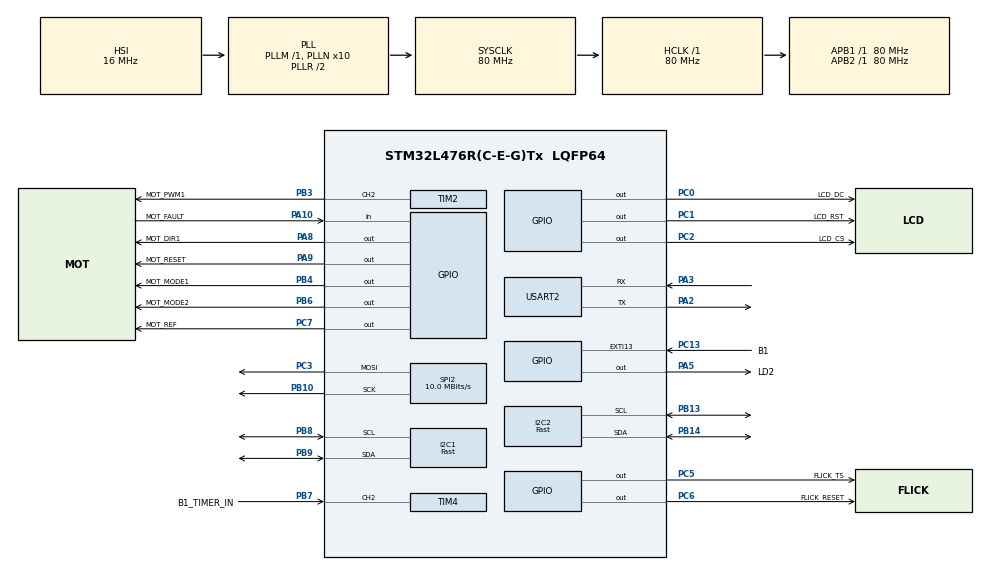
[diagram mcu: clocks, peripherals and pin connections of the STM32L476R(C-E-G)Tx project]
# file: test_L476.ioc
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I2C1.I2C_Speed_Mode=I2C_Fast
I2C1.OwnAddress=0x42
I2C1.Timing=0x00702991
I2C2.I2C_Speed_Mode=I2C_Fast
I2C2.Timing=0x00702991
Mcu.Family=STM32L4
Mcu.Name=STM32L476R(C-E-G)Tx
Mcu.Package=LQFP64
NVIC.PriorityGroup=NVIC_PRIORITYGROUP_4
NVIC.TIM2_IRQn=true\:0\:0\:false\:false\:true\:true\:true
PA10.GPIO_Label=MOT_FAULT
PA10.GPIO_Mode=GPIO_MODE_INPUT
PA10.GPIO_PuPd=GPIO_NOPULL
PA10.Signal=GPIO_Input
PA13\ (JTMS-SWDIO).Mode=Serial_Wire
PA13\ (JTMS-SWDIO).Signal=SYS_JTMS-SWDIO
PA14\ (JTCK-SWCLK).Mode=Serial_Wire
PA14\ (JTCK-SWCLK).Signal=SYS_JTCK-SWCLK
PA2.GPIO_Mode=GPIO_MODE_AF_PP
PA2.GPIO_ModeDefaultPP=GPIO_MODE_AF_PP
PA2.GPIO_PuPd=GPIO_NOPULL
PA2.GPIO_Speed=GPIO_SPEED_FREQ_VERY_HIGH
PA2.Mode=Asynchronous
PA2.Signal=USART2_TX
PA3.GPIO_Mode=GPIO_MODE_AF_PP
PA3.GPIO_ModeDefaultPP=GPIO_MODE_AF_PP
PA3.GPIO_PuPd=GPIO_NOPULL
PA3.GPIO_Speed=GPIO_SPEED_FREQ_VERY_HIGH
PA3.Mode=Asynchronous
PA3.Signal=USART2_RX
PA5.GPIO_Label=LD2
PA5.Signal=GPIO_Output
PA8.GPIO_Label=MOT_DIR1
PA8.GPIO_ModeDefaultOutputPP=GPIO_MODE_OUTPUT_PP
PA8.GPIO_PuPd=GPIO_NOPULL
PA8.GPIO_Speed=GPIO_SPEED_FREQ_LOW
PA8.PinState=GPIO_PIN_RESET
PA8.Signal=GPIO_Output
PA9.GPIO_Label=MOT_RESET
PA9.GPIO_ModeDefaultOutputPP=GPIO_MODE_OUTPUT_PP
PA9.GPIO_PuPd=GPIO_NOPULL
PA9.GPIO_Speed=GPIO_SPEED_FREQ_LOW
PA9.PinState=GPIO_PIN_RESET
PA9.Signal=GPIO_Output
PB10.GPIO_PuPd=GPIO_NOPULL
PB10.GPIO_Speed=GPIO_SPEED_FREQ_VERY_HIGH
PB10.Mode=TX_Only_Simplex_Unidirect_Master
PB10.Signal=SPI2_SCK
PB13.Mode=I2C
PB13.Signal=I2C2_SCL
PB14.Mode=I2C
PB14.Signal=I2C2_SDA
PB3\ (JTDO-TRACESWO).GPIO_Label=MOT_PWM1
PB3\ (JTDO-TRACESWO).GPIO_ModeDefaultPP=GPIO_MODE_AF_OD
PB3\ (JTDO-TRACESWO).GPIO_PuPd=GPIO_PULLUP
PB3\ (JTDO-TRACESWO).GPIO_Speed=GPIO_SPEED_FREQ_MEDIUM
PB3\ (JTDO-TRACESWO).Signal=S_TIM2_CH2
PB4\ (NJTRST).GPIO_Label=MOT_MODE1
PB4\ (NJTRST).GPIO_ModeDefaultOutputPP=GPIO_MODE_OUTPUT_PP
PB4\ (NJTRST).GPIO_PuPd=GPIO_NOPULL
PB4\ (NJTRST).GPIO_Speed=GPIO_SPEED_FREQ_LOW
PB4\ (NJTRST).PinState=GPIO_PIN_RESET
PB4\ (NJTRST).Signal=GPIO_Output
PB6.GPIO_FM6=__NULL
PB6.GPIO_Label=MOT_MODE2
PB6.GPIO_ModeDefaultOutputPP=GPIO_MODE_OUTPUT_PP
PB6.GPIO_PuPd=GPIO_NOPULL
PB6.GPIO_Speed=GPIO_SPEED_FREQ_LOW
PB6.PinState=GPIO_PIN_RESET
PB6.Signal=GPIO_Output
PB7.GPIO_Label=B1_TIMER_IN
PB7.Signal=S_TIM4_CH2
PB8.Mode=I2C
PB8.Signal=I2C1_SCL
PB9.Mode=I2C
PB9.Signal=I2C1_SDA
PC0.GPIO_Label=LCD_DC
PC0.GPIO_Speed=GPIO_SPEED_FREQ_VERY_HIGH
PC0.Signal=GPIO_Output
PC1.GPIO_Label=LCD_RST
PC1.GPIO_Speed=GPIO_SPEED_FREQ_HIGH
PC1.Signal=GPIO_Output
PC13.GPIO_Label=B1
PC13.GPIO_ModeDefaultEXTI=GPIO_MODE_IT_RISING
PC13.GPIO_PuPd=GPIO_NOPULL
PC13.Signal=GPXTI13
PC14-OSC32_IN\ (PC14).Mode=LSE-External-Oscillator
PC14-OSC32_IN\ (PC14).Signal=RCC_OSC32_IN
PC15-OSC32_OUT\ (PC15).Mode=LSE-External-Oscillator
PC15-OSC32_OUT\ (PC15).Signal=RCC_OSC32_OUT
PC2.GPIO_Label=LCD_CS
PC2.GPIO_Speed=GPIO_SPEED_FREQ_VERY_HIGH
PC2.Signal=GPIO_Output
PC3.GPIO_PuPd=GPIO_PULLUP
PC3.GPIO_Speed=GPIO_SPEED_FREQ_VERY_HIGH
PC3.Mode=TX_Only_Simplex_Unidirect_Master
PC3.Signal=SPI2_MOSI
PC5.GPIO_Label=FLICK_TS
PC5.GPIO_ModeDefaultOutputPP=GPIO_MODE_OUTPUT_OD
PC5.GPIO_PuPd=GPIO_PULLUP
PC5.GPIO_Speed=GPIO_SPEED_FREQ_HIGH
PC5.Signal=GPIO_Output
PC6.GPIO_Label=FLICK_RESET
PC6.Signal=GPIO_Output
PC7.GPIO_Label=MOT_REF
PC7.GPIO_ModeDefaultOutputPP=GPIO_MODE_OUTPUT_PP
PC7.GPIO_PuPd=GPIO_NOPULL
PC7.GPIO_Speed=GPIO_SPEED_FREQ_LOW
PC7.PinState=GPIO_PIN_RESET
PC7.Signal=GPIO_Output
PH0-OSC_IN\ (PH0).Signal=RCC_OSC_IN
PH1-OSC_OUT\ (PH1).Signal=RCC_OSC_OUT
ProjectManager.HeapSize=0x200
ProjectManager.StackSize=0x400
ProjectManager.TargetToolchain=STM32CubeIDE
RCC.ADCFreq_Value=64000000
RCC.AHBFreq_Value=80000000
RCC.APB1Freq_Value=80000000
RCC.APB1TimFreq_Value=80000000
RCC.APB2Freq_Value=80000000
RCC.APB2TimFreq_Value=80000000
RCC.CortexFreq_Value=80000000
RCC.HCLKFreq_Value=80000000
RCC.HSE_VALUE=8000000
RCC.HSI_VALUE=16000000
RCC.MSI_VALUE=4000000
RCC.PLLN=10
RCC.PLLSourceVirtual=RCC_PLLSOURCE_HSI
RCC.PREFETCH_ENABLE=1
RCC.SYSCLKFreq_VALUE=80000000
RCC.SYSCLKSource=RCC_SYSCLKSOURCE_PLLCLK
RCC.USBFreq_Value=64000000
RCC.VCOOutputFreq_Value=160000000
SH.S_TIM2_CH2.0=TIM2_CH2,PWM Generation2 CH2
SH.S_TIM4_CH2.0=TIM4_CH2,TriggerSource_TI2FP2
SPI2.BaudRatePrescaler=SPI_BAUDRATEPRESCALER_8
SPI2.CLKPhase=SPI_PHASE_1EDGE
SPI2.CalculateBaudRate=10.0 MBits/s
SPI2.DataSize=SPI_DATASIZE_8BIT
SPI2.Direction=SPI_DIRECTION_2LINES
SPI2.Mode=SPI_MODE_MASTER
SPI2.NSSPMode=SPI_NSS_PULSE_DISABLE
SPI2.VirtualType=VM_MASTER
TIM2.AutoReloadPreload=TIM_AUTORELOAD_PRELOAD_ENABLE
TIM2.Channel-PWM\ Generation2\ CH2=TIM_CHANNEL_2
TIM2.CounterMode=TIM_COUNTERMODE_DOWN
TIM2.Period=2000
TIM2.Prescaler=80
TIM2.Pulse-PWM\ Generation2\ CH2=1000
TIM2.TIM_MasterOutputTrigger=TIM_TRGO_UPDATE
TIM4.ClockDivision=TIM_CLOCKDIVISION_DIV1
TIM4.Prescaler=8000
TIM4.Slave_TriggerFilter=15
TIM4.Slave_TriggerPolarity=TIM_TRIGGERPOLARITY_FALLING
TIM4.TIM_MasterOutputTrigger=TIM_TRGO_ENABLE
USART2.VirtualMode-Asynchronous=VM_ASYNC
VP_TIM2_VS_ClockSourceINT.Mode=Internal
VP_TIM4_VS_ClockSourceINT.Mode=Internal
VP_TIM4_VS_ControllerModeGated.Mode=Gated Mode
board=NUCLEO-L476RG

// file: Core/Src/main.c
/* USER CODE BEGIN Header */
/**
 ******************************************************************************
 * @file           : main.c
 * @brief          : STM32L476 Nucleo-64 Workbench Tests @ WUT Mchtr
 ******************************************************************************
 * @attention
 *
 * Copyright (c) 2020 STMicroelectronics.<br>
 * Copyright (c) 2021 Mateusz Szumilas @ WUT Faculty of Mechatronics.<br>
 * All rights reserved.
 *
 * This software component is licensed under BSD 3-Clause license,
 * the "License"; You may not use this file except in compliance with the
 * License. You may obtain a copy of the License at:
 *                        opensource.org/licenses/BSD-3-Clause
 *
 ******************************************************************************
 */
/* USER CODE END Header */
#include "main.h"

/* USER CODE BEGIN Includes */
#include "string.h"
#include "stdio.h"
#include "stm32_adafruit_lcd.h"
#include "flick.h"
#include "lsm6ds33_reg.h"
#include "math.h"
/* USER CODE END Includes */

I2C_HandleTypeDef hi2c1;
I2C_HandleTypeDef hi2c2;

SPI_HandleTypeDef hspi2;

TIM_HandleTypeDef htim2;
TIM_HandleTypeDef htim4;

UART_HandleTypeDef huart2;

double kat_obecny; //dane z funkci IMU
_Bool tryb; // = 0; //ogólnie to użytkownik to będzie podawał poprzez GUI
double kat_start; // = 30; //ogólnie to użytkownik to będzie podawał poprzez GUI
double kat_obr;// = 60; //ogólnie to użytkownik to będzie podawał poprzez GUI
int opuszczenie = 0; //warunek opuszczenia trybu 1 ustawinay przez gest z Flicka

/* USER CODE BEGIN PV */

I2C_HandleTypeDef *hi2cflick = &hi2c1;

SPI_HandleTypeDef *hnucleo_Spi = &hspi2;

int pulse_cnt; //zmienna liczba impulsów

/* USER CODE END PV */

void SystemClock_Config(void);
static void MX_GPIO_Init(void);
static void MX_USART2_UART_Init(void);
static void MX_TIM4_Init(void);
static void MX_TIM2_Init(void);
static void MX_SPI2_Init(void);
static void MX_I2C1_Init(void);
static void MX_I2C2_Init(void);

/* USER CODE BEGIN 0 */

void Pulse_Counter(void) //proces do zliczania impulsów
{
	if (pulse_cnt > 0) pulse_cnt--;
	else
	{
		HAL_TIM_PWM_Stop_IT(&htim2, TIM_CHANNEL_2); //odliczamy ilosć impulsów wygenerowanych w PWM timera 2 (ma przerwanie co jeden impuls)
		__HAL_TIM_SET_COUNTER(&htim2, 2000); //długość cyklu (licznik który określa nam jak długie są impulsy)

		//Można zmienić COUNTER aby było wolniej szybciej (zmienia tylko czas), ale ogólnie tak jak jest to jest spoko

		//zegar to 1000000 impulsów na sekundę (wartość 2000 w ustawieniach timera ma zwiazek z tym co tutaj w funkcji ustawiamy)

		//licznik "ładujemy do 2000 impulsów i liczymy w dół => 2000*1/1000000s = 0,002 s

		//2000 nie ustawione jest bez znaczenia
		//w liczniku ustawiamy też wartosć 1000 i to ma zwiazek z przebiegiem (jak długie i o jakim wypełnieniu impulsy otrzymamy)

	}
}

/* USER CODE END 0 */

/**
 * Informacje wstępne
 *
 * przełożenie przekładni i=10
 * mikrokroki 1/16
 * na pełen obrót stołu nalezy wykonać 32000 mikrokroków
 */

int main(void)
{

  /* MCU Configuration--------------------------------------------------------*/

  /* Reset of all peripherals, Initializes the Flash interface and the Systick. */
  HAL_Init();

  /* Configure the system clock */
  SystemClock_Config();

  /* Initialize all configured peripherals */
  MX_GPIO_Init();
  MX_USART2_UART_Init();
  MX_TIM4_Init();
  MX_TIM2_Init();
  MX_SPI2_Init();
  MX_I2C1_Init();
  MX_I2C2_Init();
  /* USER CODE BEGIN 2 */

	/* Stepstick */
	HAL_TIM_Base_Start(&htim4);

	HAL_GPIO_WritePin(MOT_RESET_GPIO_Port, MOT_RESET_Pin, GPIO_PIN_RESET);
	HAL_GPIO_WritePin(MOT_MODE1_GPIO_Port, MOT_MODE1_Pin, GPIO_PIN_RESET);
	HAL_GPIO_WritePin(MOT_MODE2_GPIO_Port, MOT_MODE2_Pin, GPIO_PIN_SET);
	HAL_GPIO_WritePin(MOT_RESET_GPIO_Port, MOT_RESET_Pin, GPIO_PIN_SET);

	/* LCD */
	BSP_LCD_Init();
	BSP_LCD_DisplayOn();

	BSP_LCD_DisplayStringAtLine(2, (uint8_t *) "testTestTest");

	BSP_LCD_Clear(LCD_COLOR_YELLOW);

	BSP_LCD_DisplayStringAtLine(3, (uint8_t *) "test");

	/* Sensors */
	HAL_I2C_Init(&hi2c1);
	HAL_I2C_Init(&hi2c2);

	/* Flick */
	flick_reset();
	flick_set_param(0x90, 0x20, 0x20);

	/* IMU */
	uint8_t i2c2_buf[10];
	HAL_I2C_Mem_Read(&hi2c2, ACC_GYRO_ADDR, WHO_AM_I, I2C_MEMADD_SIZE_8BIT, i2c2_buf, 1, 1);
	HAL_I2C_Mem_Read(&hi2c2, 0x1e<<1, 0x0f, I2C_MEMADD_SIZE_8BIT, i2c2_buf+1, 1, 1);

	char str[40];
	sprintf(str, "Who? A/G:%02x M:%02x", i2c2_buf[0], i2c2_buf[1]);
	BSP_LCD_DisplayStringAtLine(10, (uint8_t *) str);

	/* cfg gyro */
	i2c2_buf[0] = 0x38;		// enable X,Y,Z axes
	HAL_I2C_Mem_Write(&hi2c2, ACC_GYRO_ADDR, CTRL10_C, I2C_MEMADD_SIZE_8BIT, i2c2_buf, 1, 1);
	i2c2_buf[0] = 0x14;		// 13 Hz ODR, 500 dps
	HAL_I2C_Mem_Write(&hi2c2, ACC_GYRO_ADDR, CTRL2_G, I2C_MEMADD_SIZE_8BIT, i2c2_buf, 1, 1);

	// cfg acc
	i2c2_buf[0] = 0x38;		// enable X,Y,Z axes
	HAL_I2C_Mem_Write(&hi2c2, ACC_GYRO_ADDR, CTRL9_XL, I2C_MEMADD_SIZE_8BIT, i2c2_buf, 1, 1);
	i2c2_buf[0] = 0x10;		// 13 Hz ODR, +/- 2 g
	HAL_I2C_Mem_Write(&hi2c2, ACC_GYRO_ADDR, CTRL1_XL, I2C_MEMADD_SIZE_8BIT, i2c2_buf, 1, 1);

  /* USER CODE END 2 */

  /* Infinite loop */
	while (1)
	{

	  /* USER CODE BEGIN 3 */

		uint32_t gesture, touch;
		airwheel_data_t airwheel;
		char str[20];

		flick_poll_data(&gesture, &touch, &airwheel);

		if(airwheel.new_data == FLICK_NEW_DATA)
		{
			BSP_LCD_Clear(LCD_COLOR_YELLOW);
			BSP_LCD_DrawCircle(50, 110, 22);
			BSP_LCD_FillCircle(50, 110, 12);

			sprintf(str, "pos: %02d cnt: %02d", airwheel.position, airwheel.count);
			BSP_LCD_DisplayStringAtLine(4, (uint8_t *) str);

			uint8_t circy = 110 - 12 * sin(2*3.1416*airwheel.position/32);
			uint8_t circx = 50 - 12 * cos(2*3.1416*airwheel.position/32);

			BSP_LCD_FillCircle(circx, circy, 3);

			airwheel.new_data = FLICK_NO_DATA;
		}

		sprintf(str, "g:%lx             ", gesture);
		BSP_LCD_DisplayStringAtLine(1, (uint8_t *) str);
		sprintf(str, "gest:%d           ", (uint8_t) gesture);
		BSP_LCD_DisplayStringAtLine(2, (uint8_t *) str);
		sprintf(str, "t:%lx             ", touch);
		BSP_LCD_DisplayStringAtLine(3, (uint8_t *) str);

		/* IMU */
		HAL_I2C_Mem_Read(&hi2c2, ACC_GYRO_ADDR, STATUS_REG, I2C_MEMADD_SIZE_8BIT, i2c2_buf, 1, 1);
		uint8_t tmp_stat = i2c2_buf[0];
		if (tmp_stat & SR_XLDA)
		{
			HAL_I2C_Mem_Read(&hi2c2, ACC_GYRO_ADDR, OUTX_L_XL, I2C_MEMADD_SIZE_8BIT, i2c2_buf, 6, 1);
			sprintf(str, "acc %+4hi%+4hi%+4hi",
					(int8_t)*(i2c2_buf+1), (int8_t)*(i2c2_buf+3), (int8_t)*(i2c2_buf+5));
			BSP_LCD_DisplayStringAtLine(12, (uint8_t *) str);
		}
		if (tmp_stat & SR_GDA)
		{
			HAL_I2C_Mem_Read(&hi2c2, ACC_GYRO_ADDR, OUTX_L_G, I2C_MEMADD_SIZE_8BIT, i2c2_buf, 6, 1);
			sprintf(str, "gyro %+4hi%+4hi%+4hi",
					(int8_t)*(i2c2_buf+1), (int8_t)*(i2c2_buf+3), (int8_t)*(i2c2_buf+5));
			BSP_LCD_DisplayStringAtLine(11, (uint8_t *) str);
		}

		HAL_Delay(100);

//		if (HAL_GPIO_ReadPin(B1_GPIO_Port, B1_Pin) == GPIO_PIN_RESET)
//		{
//			pulse_cnt = 500;	//ilość impulsów o jaki silnik ma się poruszyć (ruch zależy od ustawień stepsticka)_MW
//			HAL_TIM_PWM_Start_IT(&htim2, TIM_CHANNEL_2); //uruchomienie PWM czyli generowania impulsów i my tu nie zostajemy (kroki się wykonują.
//			//To jest tylko utuchomienie timera z obsługą przerwania
//			//Nie ma potrzeby się tu pokazywać dopóki te kroki się nie wykonają
//
//			//należy zadawać co jakiś czas określoną liczbę kroków i wmiedzy czasie odczytywać inne wartosci (zwolnić moc obliczeniową)
//		}

		Screen_Motor_Steering(uint16_t gesture_2); // funkcja GUI do rozpoznania trybu (tryb), wymaga wpisania przez zespół GUI poprawnych parametrów wywołania funkcji
		Angle_menu(const wchar_t *Title, uint16_t current_angle, int Mode); // funkcja GUI do obliczenia wartości kat_start i kat_obr, wymaga wpisania przez zespół GUI poprawnych parametrów wywołania funkcji
		tryb = zmienna_z_funkcji_Screen_Motor_Steering; // dopisać nazwę zmiennej globalnej
		kat_start = start_angle; //ogólnie to użytkownik to będzie podawał poprzez GUI

		euler();
		kat_obecny = eulerAngles[2] * 180 / 3,14; //odczytanie bieżącego kąta, GUI pobira tą wartość
		Current_angle_screen(kat_obecny); // przekazanie kąta obecnego na screen do GUI
		HAL_GPIO_WritePin(GPIOA, MOT_WARUNEK_OPUSZCZENIA, GPIO_PIN_RESET);

		if(tryb == 0) //Wejście do trybu 0, poruszamy się z kierunka A do kierunku B
		{

			euler();
			kat_obecny = eulerAngles[2] * 180 / 3,14; //odczytanie bieżącego kąta, GUI pobira tą wartość
			Current_angle_screen(kat_obecny); // przekazanie kąta obecnego na screen do GUI

			kat_obr = rot_angle; //ogólnie to użytkownik to będzie podawał poprzez GUI

			while(!((kat_start - 2) <= kat_obecny && kat_obecny <= (kat_start + 2))) //ustawienie na pozycje startową
			{

				euler();
				kat_obecny = eulerAngles[2] * 180 / 3,14; //odczytanie bieżącego kąta, GUI pobira tą wartość
				Current_angle_screen(kat_obecny); // przekazanie kąta obecnego na screen do GUI

				if(0 <= (kat_obecny - kat_start))
				{

					HAL_GPIO_WritePin(GPIOA, MOT_DIR1_Pin, GPIO_PIN_SET); //ustawienie obrotów w lewo
					pulse_cnt = (abs(kat_obecny - kat_start)) * 32000 / 360; //2000 // mikrokroki na kąt i mnożone przez kąt obrotu
					HAL_TIM_PWM_Start_IT(&htim2, TIM_CHANNEL_2);

				}
				if(0 > (kat_obecny - kat_start))
				{
					HAL_GPIO_WritePin(GPIOA, MOT_DIR1_Pin, GPIO_PIN_RESET); //ustawienie obrotów w prawo
					pulse_cnt = (abs(kat_obecny - kat_start)) * 32000 / 360;
					HAL_TIM_PWM_Start_IT(&htim2, TIM_CHANNEL_2);
				}

			}

			while(!((kat_start + kat_obr - 2) <= kat_obecny && kat_obecny <= (kat_start + kat_obr + 2))) //przemieszczanie sie z kierunku A na kierunek B
			{

				euler();
				kat_obecny = eulerAngles[2] * 180 / 3,14; //odczytanie bieżącego kąta, GUI pobira tą wartość
				Current_angle_screen(kat_obecny); // przekazanie kąta obecnego na screen do GUI

				if(kat_obecny >= kat_start + kat_obr)
				{
					HAL_GPIO_WritePin(GPIOA, MOT_DIR1_Pin, GPIO_PIN_SET); //ustawienie obrotów w lewo
					pulse_cnt = (abs(kat_start + kat_obr - kat_obecny)) * 32000 / 360;
					HAL_TIM_PWM_Start_IT(&htim2, TIM_CHANNEL_2);
				}

				if(kat_obecny < kat_start + kat_obr)
				{
					HAL_GPIO_WritePin(GPIOA, MOT_DIR1_Pin, GPIO_PIN_RESET); //ustawienie obrotów w prawo
					pulse_cnt = (abs(kat_start + kat_obr - kat_obecny)) * 32000 / 360;
					HAL_TIM_PWM_Start_IT(&htim2, TIM_CHANNEL_2);
				}

			}

		}

		if(tryb == 1)
		{
			while(!(opuszcenie == 1)) //podążanie za pozycją startową z stałą prędkością
			{

				euler();
				kat_obecny = eulerAngles[2] * 180 / 3,14; //odczytanie bieżącego kąta, GUI pobira tą wartość
				Current_angle_screen(kat_obecny); // przekazanie kąta obecnego na screen do GUI

				if(0 <= kat_obecny - kat_start)
				{
					HAL_GPIO_WritePin(GPIOA, MOT_DIR1_Pin, GPIO_PIN_SET); //ustawienie obrotów w lewo
					pulse_cnt = (abs(kat_obecny - kat_start)) * 32000 / 360;
					HAL_TIM_PWM_Start_IT(&htim2, TIM_CHANNEL_2);
				}
				if(0 >= kat_obecny - kat_start)
				{
					HAL_GPIO_WritePin(GPIOA, MOT_DIR1_Pin, GPIO_PIN_RESET); //ustawienie obrotów w prawo
					pulse_cnt = (abs(kat_obecny - kat_start)) * 32000 / 360;
					HAL_TIM_PWM_Start_IT(&htim2, TIM_CHANNEL_2);
				}

				if(funckja_sprawdzenie_gestu == 1) //sprawdzenie czy użytkownik chce wyjść z petli
				{
					opuszczenie = 1;
				}

			}
		}
	}
  /* USER CODE END 3 */
}

void SystemClock_Config(void)
{
  RCC_OscInitTypeDef RCC_OscInitStruct = {0};
  RCC_ClkInitTypeDef RCC_ClkInitStruct = {0};
  RCC_PeriphCLKInitTypeDef PeriphClkInit = {0};

  /** Initializes the RCC Oscillators according to the specified parameters
  * in the RCC_OscInitTypeDef structure.
  */
  RCC_OscInitStruct.OscillatorType = RCC_OSCILLATORTYPE_HSI;
  RCC_OscInitStruct.HSIState = RCC_HSI_ON;
  RCC_OscInitStruct.HSICalibrationValue = RCC_HSICALIBRATION_DEFAULT;
  RCC_OscInitStruct.PLL.PLLState = RCC_PLL_ON;
  RCC_OscInitStruct.PLL.PLLSource = RCC_PLLSOURCE_HSI;
  RCC_OscInitStruct.PLL.PLLM = 1;
  RCC_OscInitStruct.PLL.PLLN = 10;
  RCC_OscInitStruct.PLL.PLLP = RCC_PLLP_DIV7;
  RCC_OscInitStruct.PLL.PLLQ = RCC_PLLQ_DIV2;
  RCC_OscInitStruct.PLL.PLLR = RCC_PLLR_DIV2;
  if (HAL_RCC_OscConfig(&RCC_OscInitStruct) != HAL_OK)
  {
    Error_Handler();
  }
  /** Initializes the CPU, AHB and APB buses clocks
  */
  RCC_ClkInitStruct.ClockType = RCC_CLOCKTYPE_HCLK|RCC_CLOCKTYPE_SYSCLK
                              |RCC_CLOCKTYPE_PCLK1|RCC_CLOCKTYPE_PCLK2;
  RCC_ClkInitStruct.SYSCLKSource = RCC_SYSCLKSOURCE_PLLCLK;
  RCC_ClkInitStruct.AHBCLKDivider = RCC_SYSCLK_DIV1;
  RCC_ClkInitStruct.APB1CLKDivider = RCC_HCLK_DIV1;
  RCC_ClkInitStruct.APB2CLKDivider = RCC_HCLK_DIV1;

  if (HAL_RCC_ClockConfig(&RCC_ClkInitStruct, FLASH_LATENCY_4) != HAL_OK)
  {
    Error_Handler();
  }
  PeriphClkInit.PeriphClockSelection = RCC_PERIPHCLK_USART2|RCC_PERIPHCLK_I2C1
                              |RCC_PERIPHCLK_I2C2;
  PeriphClkInit.Usart2ClockSelection = RCC_USART2CLKSOURCE_PCLK1;
  PeriphClkInit.I2c1ClockSelection = RCC_I2C1CLKSOURCE_PCLK1;
  PeriphClkInit.I2c2ClockSelection = RCC_I2C2CLKSOURCE_PCLK1;
  if (HAL_RCCEx_PeriphCLKConfig(&PeriphClkInit) != HAL_OK)
  {
    Error_Handler();
  }
  /** Configure the main internal regulator output voltage
  */
  if (HAL_PWREx_ControlVoltageScaling(PWR_REGULATOR_VOLTAGE_SCALE1) != HAL_OK)
  {
    Error_Handler();
  }
}

static void MX_I2C1_Init(void)
{

  hi2c1.Instance = I2C1;
  hi2c1.Init.Timing = 0x00702991;
  hi2c1.Init.OwnAddress1 = 132;
  hi2c1.Init.AddressingMode = I2C_ADDRESSINGMODE_7BIT;
  hi2c1.Init.DualAddressMode = I2C_DUALADDRESS_DISABLE;
  hi2c1.Init.OwnAddress2 = 0;
  hi2c1.Init.OwnAddress2Masks = I2C_OA2_NOMASK;
  hi2c1.Init.GeneralCallMode = I2C_GENERALCALL_DISABLE;
  hi2c1.Init.NoStretchMode = I2C_NOSTRETCH_DISABLE;
  if (HAL_I2C_Init(&hi2c1) != HAL_OK)
  {
    Error_Handler();
  }
  /** Configure Analogue filter
  */
  if (HAL_I2CEx_ConfigAnalogFilter(&hi2c1, I2C_ANALOGFILTER_ENABLE) != HAL_OK)
  {
    Error_Handler();
  }
  /** Configure Digital filter
  */
  if (HAL_I2CEx_ConfigDigitalFilter(&hi2c1, 0) != HAL_OK)
  {
    Error_Handler();
  }

}

static void MX_I2C2_Init(void)
{

  hi2c2.Instance = I2C2;
  hi2c2.Init.Timing = 0x00702991;
  hi2c2.Init.OwnAddress1 = 0;
  hi2c2.Init.AddressingMode = I2C_ADDRESSINGMODE_7BIT;
  hi2c2.Init.DualAddressMode = I2C_DUALADDRESS_DISABLE;
  hi2c2.Init.OwnAddress2 = 0;
  hi2c2.Init.OwnAddress2Masks = I2C_OA2_NOMASK;
  hi2c2.Init.GeneralCallMode = I2C_GENERALCALL_DISABLE;
  hi2c2.Init.NoStretchMode = I2C_NOSTRETCH_DISABLE;
  if (HAL_I2C_Init(&hi2c2) != HAL_OK)
  {
    Error_Handler();
  }
  /** Configure Analogue filter
  */
  if (HAL_I2CEx_ConfigAnalogFilter(&hi2c2, I2C_ANALOGFILTER_ENABLE) != HAL_OK)
  {
    Error_Handler();
  }
  /** Configure Digital filter
  */
  if (HAL_I2CEx_ConfigDigitalFilter(&hi2c2, 0) != HAL_OK)
  {
    Error_Handler();
  }

}

static void MX_SPI2_Init(void)
{

  /* SPI2 parameter configuration*/
  hspi2.Instance = SPI2;
  hspi2.Init.Mode = SPI_MODE_MASTER;
  hspi2.Init.Direction = SPI_DIRECTION_2LINES;
  hspi2.Init.DataSize = SPI_DATASIZE_8BIT;
  hspi2.Init.CLKPolarity = SPI_POLARITY_LOW;
  hspi2.Init.CLKPhase = SPI_PHASE_1EDGE;
  hspi2.Init.NSS = SPI_NSS_SOFT;
  hspi2.Init.BaudRatePrescaler = SPI_BAUDRATEPRESCALER_8;
  hspi2.Init.FirstBit = SPI_FIRSTBIT_MSB;
  hspi2.Init.TIMode = SPI_TIMODE_DISABLE;
  hspi2.Init.CRCCalculation = SPI_CRCCALCULATION_DISABLE;
  hspi2.Init.CRCPolynomial = 7;
  hspi2.Init.CRCLength = SPI_CRC_LENGTH_DATASIZE;
  hspi2.Init.NSSPMode = SPI_NSS_PULSE_DISABLE;
  if (HAL_SPI_Init(&hspi2) != HAL_OK)
  {
    Error_Handler();
  }

}

static void MX_TIM2_Init(void)
{

  TIM_ClockConfigTypeDef sClockSourceConfig = {0};
  TIM_MasterConfigTypeDef sMasterConfig = {0};
  TIM_OC_InitTypeDef sConfigOC = {0};

  htim2.Instance = TIM2;
  htim2.Init.Prescaler = 80;
  htim2.Init.CounterMode = TIM_COUNTERMODE_DOWN;
  htim2.Init.Period = 2000;
  htim2.Init.ClockDivision = TIM_CLOCKDIVISION_DIV1;
  htim2.Init.AutoReloadPreload = TIM_AUTORELOAD_PRELOAD_ENABLE;
  if (HAL_TIM_Base_Init(&htim2) != HAL_OK)
  {
    Error_Handler();
  }
  sClockSourceConfig.ClockSource = TIM_CLOCKSOURCE_INTERNAL;
  if (HAL_TIM_ConfigClockSource(&htim2, &sClockSourceConfig) != HAL_OK)
  {
    Error_Handler();
  }
  if (HAL_TIM_PWM_Init(&htim2) != HAL_OK)
  {
    Error_Handler();
  }
  sMasterConfig.MasterOutputTrigger = TIM_TRGO_UPDATE;
  sMasterConfig.MasterSlaveMode = TIM_MASTERSLAVEMODE_DISABLE;
  if (HAL_TIMEx_MasterConfigSynchronization(&htim2, &sMasterConfig) != HAL_OK)
  {
    Error_Handler();
  }
  sConfigOC.OCMode = TIM_OCMODE_PWM1;
  sConfigOC.Pulse = 1000;
  sConfigOC.OCPolarity = TIM_OCPOLARITY_HIGH;
  sConfigOC.OCFastMode = TIM_OCFAST_DISABLE;
  if (HAL_TIM_PWM_ConfigChannel(&htim2, &sConfigOC, TIM_CHANNEL_2) != HAL_OK)
  {
    Error_Handler();
  }
  HAL_TIM_MspPostInit(&htim2);

}

static void MX_TIM4_Init(void)
{

  TIM_ClockConfigTypeDef sClockSourceConfig = {0};
  TIM_SlaveConfigTypeDef sSlaveConfig = {0};
  TIM_MasterConfigTypeDef sMasterConfig = {0};

  htim4.Instance = TIM4;
  htim4.Init.Prescaler = 8000;
  htim4.Init.CounterMode = TIM_COUNTERMODE_UP;
  htim4.Init.Period = 65535;
  htim4.Init.ClockDivision = TIM_CLOCKDIVISION_DIV1;
  htim4.Init.AutoReloadPreload = TIM_AUTORELOAD_PRELOAD_DISABLE;
  if (HAL_TIM_Base_Init(&htim4) != HAL_OK)
  {
    Error_Handler();
  }
  sClockSourceConfig.ClockSource = TIM_CLOCKSOURCE_INTERNAL;
  if (HAL_TIM_ConfigClockSource(&htim4, &sClockSourceConfig) != HAL_OK)
  {
    Error_Handler();
  }
  sSlaveConfig.SlaveMode = TIM_SLAVEMODE_GATED;
  sSlaveConfig.InputTrigger = TIM_TS_TI2FP2;
  sSlaveConfig.TriggerPolarity = TIM_TRIGGERPOLARITY_FALLING;
  sSlaveConfig.TriggerFilter = 15;
  if (HAL_TIM_SlaveConfigSynchro(&htim4, &sSlaveConfig) != HAL_OK)
  {
    Error_Handler();
  }
  sMasterConfig.MasterOutputTrigger = TIM_TRGO_ENABLE;
  sMasterConfig.MasterSlaveMode = TIM_MASTERSLAVEMODE_DISABLE;
  if (HAL_TIMEx_MasterConfigSynchronization(&htim4, &sMasterConfig) != HAL_OK)
  {
    Error_Handler();
  }

}

static void MX_USART2_UART_Init(void)
{

  huart2.Instance = USART2;
  huart2.Init.BaudRate = 115200;
  huart2.Init.WordLength = UART_WORDLENGTH_8B;
  huart2.Init.StopBits = UART_STOPBITS_1;
  huart2.Init.Parity = UART_PARITY_NONE;
  huart2.Init.Mode = UART_MODE_TX_RX;
  huart2.Init.HwFlowCtl = UART_HWCONTROL_NONE;
  huart2.Init.OverSampling = UART_OVERSAMPLING_16;
  huart2.Init.OneBitSampling = UART_ONE_BIT_SAMPLE_DISABLE;
  huart2.AdvancedInit.AdvFeatureInit = UART_ADVFEATURE_NO_INIT;
  if (HAL_UART_Init(&huart2) != HAL_OK)
  {
    Error_Handler();
  }

}

static void MX_GPIO_Init(void)
{
  GPIO_InitTypeDef GPIO_InitStruct = {0};

  /* GPIO Ports Clock Enable */
  __HAL_RCC_GPIOC_CLK_ENABLE();
  __HAL_RCC_GPIOH_CLK_ENABLE();
  __HAL_RCC_GPIOA_CLK_ENABLE();
  __HAL_RCC_GPIOB_CLK_ENABLE();

  /*Configure GPIO pin Output Level */
  HAL_GPIO_WritePin(GPIOC, LCD_DC_Pin|LCD_RST_Pin|LCD_CS_Pin|FLICK_TS_Pin
                          |FLICK_RESET_Pin|MOT_REF_Pin, GPIO_PIN_RESET);

  /*Configure GPIO pin Output Level */
  HAL_GPIO_WritePin(GPIOA, LD2_Pin|MOT_DIR1_Pin|MOT_RESET_Pin|MOT_WARUNEK_OPUSZCZENIA_Pin, GPIO_PIN_RESET);

  /*Configure GPIO pin Output Level */
  HAL_GPIO_WritePin(GPIOB, MOT_MODE1_Pin|MOT_MODE2_Pin, GPIO_PIN_RESET);

  /*Configure GPIO pin : B1_Pin */
  GPIO_InitStruct.Pin = B1_Pin;
  GPIO_InitStruct.Mode = GPIO_MODE_IT_RISING;
  GPIO_InitStruct.Pull = GPIO_NOPULL;
  HAL_GPIO_Init(B1_GPIO_Port, &GPIO_InitStruct);

  /*Configure GPIO pins : LCD_DC_Pin LCD_CS_Pin */
  GPIO_InitStruct.Pin = LCD_DC_Pin|LCD_CS_Pin;
  GPIO_InitStruct.Mode = GPIO_MODE_OUTPUT_PP;
  GPIO_InitStruct.Pull = GPIO_NOPULL;
  GPIO_InitStruct.Speed = GPIO_SPEED_FREQ_VERY_HIGH;
  HAL_GPIO_Init(GPIOC, &GPIO_InitStruct);

  /*Configure GPIO pin : LCD_RST_Pin */
  GPIO_InitStruct.Pin = LCD_RST_Pin;
  GPIO_InitStruct.Mode = GPIO_MODE_OUTPUT_PP;
  GPIO_InitStruct.Pull = GPIO_NOPULL;
  GPIO_InitStruct.Speed = GPIO_SPEED_FREQ_HIGH;
  HAL_GPIO_Init(LCD_RST_GPIO_Port, &GPIO_InitStruct);

  /*Configure GPIO pins : LD2_Pin MOT_DIR1_Pin MOT_RESET_Pin MOT_WARUNEK_OPUSZCZENIA_Pin */
  GPIO_InitStruct.Pin = LD2_Pin|MOT_DIR1_Pin|MOT_RESET_Pin|MOT_WARUNEK_OPUSZCZENIA_Pin;
  GPIO_InitStruct.Mode = GPIO_MODE_OUTPUT_PP;
  GPIO_InitStruct.Pull = GPIO_NOPULL;
  GPIO_InitStruct.Speed = GPIO_SPEED_FREQ_LOW;
  HAL_GPIO_Init(GPIOA, &GPIO_InitStruct);

  /*Configure GPIO pin : FLICK_TS_Pin */
  GPIO_InitStruct.Pin = FLICK_TS_Pin;
  GPIO_InitStruct.Mode = GPIO_MODE_OUTPUT_OD;
  GPIO_InitStruct.Pull = GPIO_PULLUP;
  GPIO_InitStruct.Speed = GPIO_SPEED_FREQ_HIGH;
  HAL_GPIO_Init(FLICK_TS_GPIO_Port, &GPIO_InitStruct);

  /*Configure GPIO pins : FLICK_RESET_Pin MOT_REF_Pin */
  GPIO_InitStruct.Pin = FLICK_RESET_Pin|MOT_REF_Pin;
  GPIO_InitStruct.Mode = GPIO_MODE_OUTPUT_PP;
  GPIO_InitStruct.Pull = GPIO_NOPULL;
  GPIO_InitStruct.Speed = GPIO_SPEED_FREQ_LOW;
  HAL_GPIO_Init(GPIOC, &GPIO_InitStruct);

  /*Configure GPIO pin : MOT_FAULT_Pin */
  GPIO_InitStruct.Pin = MOT_FAULT_Pin;
  GPIO_InitStruct.Mode = GPIO_MODE_INPUT;
  GPIO_InitStruct.Pull = GPIO_NOPULL;
  HAL_GPIO_Init(MOT_FAULT_GPIO_Port, &GPIO_InitStruct);

  /*Configure GPIO pins : MOT_MODE1_Pin MOT_MODE2_Pin */
  GPIO_InitStruct.Pin = MOT_MODE1_Pin|MOT_MODE2_Pin;
  GPIO_InitStruct.Mode = GPIO_MODE_OUTPUT_PP;
  GPIO_InitStruct.Pull = GPIO_NOPULL;
  GPIO_InitStruct.Speed = GPIO_SPEED_FREQ_LOW;
  HAL_GPIO_Init(GPIOB, &GPIO_InitStruct);

}

void Error_Handler(void)
{
}

/************************ (C) COPYRIGHT STMicroelectronics *****END OF FILE****/
